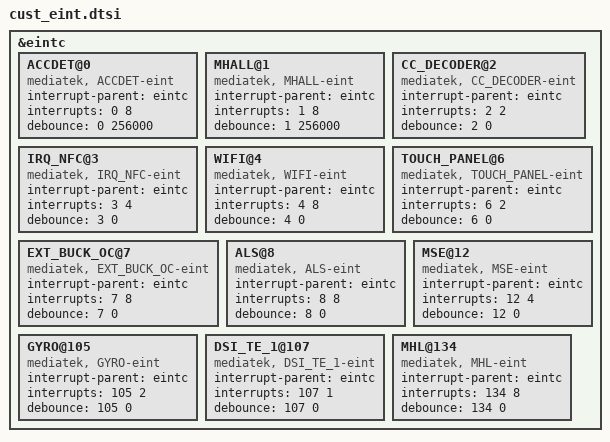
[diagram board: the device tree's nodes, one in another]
/*
 * Generated by MTK SP DrvGen Version 03.13.6 for MT6795. Copyright MediaTek Inc. (C) 2013.
 * Mon Feb 29 11:07:45 2016
 * Do Not Modify the File.
 */

/*************************
 * EINT DTSI File
*************************/

&eintc {
	ACCDET@0 {
		compatible = "mediatek, ACCDET-eint";
		interrupt-parent = <&eintc>;
		interrupts = <0 8>;
		debounce = <0 256000>;
	};

	MHALL@1 {
		compatible = "mediatek, MHALL-eint";
		interrupt-parent = <&eintc>;
		interrupts = <1 8>;
		debounce = <1 256000>;
	};

	CC_DECODER@2 {
		compatible = "mediatek, CC_DECODER-eint";
		interrupt-parent = <&eintc>;
		interrupts = <2 2>;
		debounce = <2 0>;
	};

	IRQ_NFC@3 {
		compatible = "mediatek, IRQ_NFC-eint";
		interrupt-parent = <&eintc>;
		interrupts = <3 4>;
		debounce = <3 0>;
	};

	WIFI@4 {
		compatible = "mediatek, WIFI-eint";
		interrupt-parent = <&eintc>;
		interrupts = <4 8>;
		debounce = <4 0>;
	};

	TOUCH_PANEL@6 {
		compatible = "mediatek, TOUCH_PANEL-eint";
		interrupt-parent = <&eintc>;
		interrupts = <6 2>;
		debounce = <6 0>;
	};

	EXT_BUCK_OC@7 {
		compatible = "mediatek, EXT_BUCK_OC-eint";
		interrupt-parent = <&eintc>;
		interrupts = <7 8>;
		debounce = <7 0>;
	};

	ALS@8 {
		compatible = "mediatek, ALS-eint";
		interrupt-parent = <&eintc>;
		interrupts = <8 8>;
		debounce = <8 0>;
	};

	MSE@12 {
		compatible = "mediatek, MSE-eint";
		interrupt-parent = <&eintc>;
		interrupts = <12 4>;
		debounce = <12 0>;
	};

	GYRO@105 {
		compatible = "mediatek, GYRO-eint";
		interrupt-parent = <&eintc>;
		interrupts = <105 2>;
		debounce = <105 0>;
	};

	DSI_TE_1@107 {
		compatible = "mediatek, DSI_TE_1-eint";
		interrupt-parent = <&eintc>;
		interrupts = <107 1>;
		debounce = <107 0>;
	};

	MHL@134 {
		compatible = "mediatek, MHL-eint";
		interrupt-parent = <&eintc>;
		interrupts = <134 8>;
		debounce = <134 0>;
	};

};
